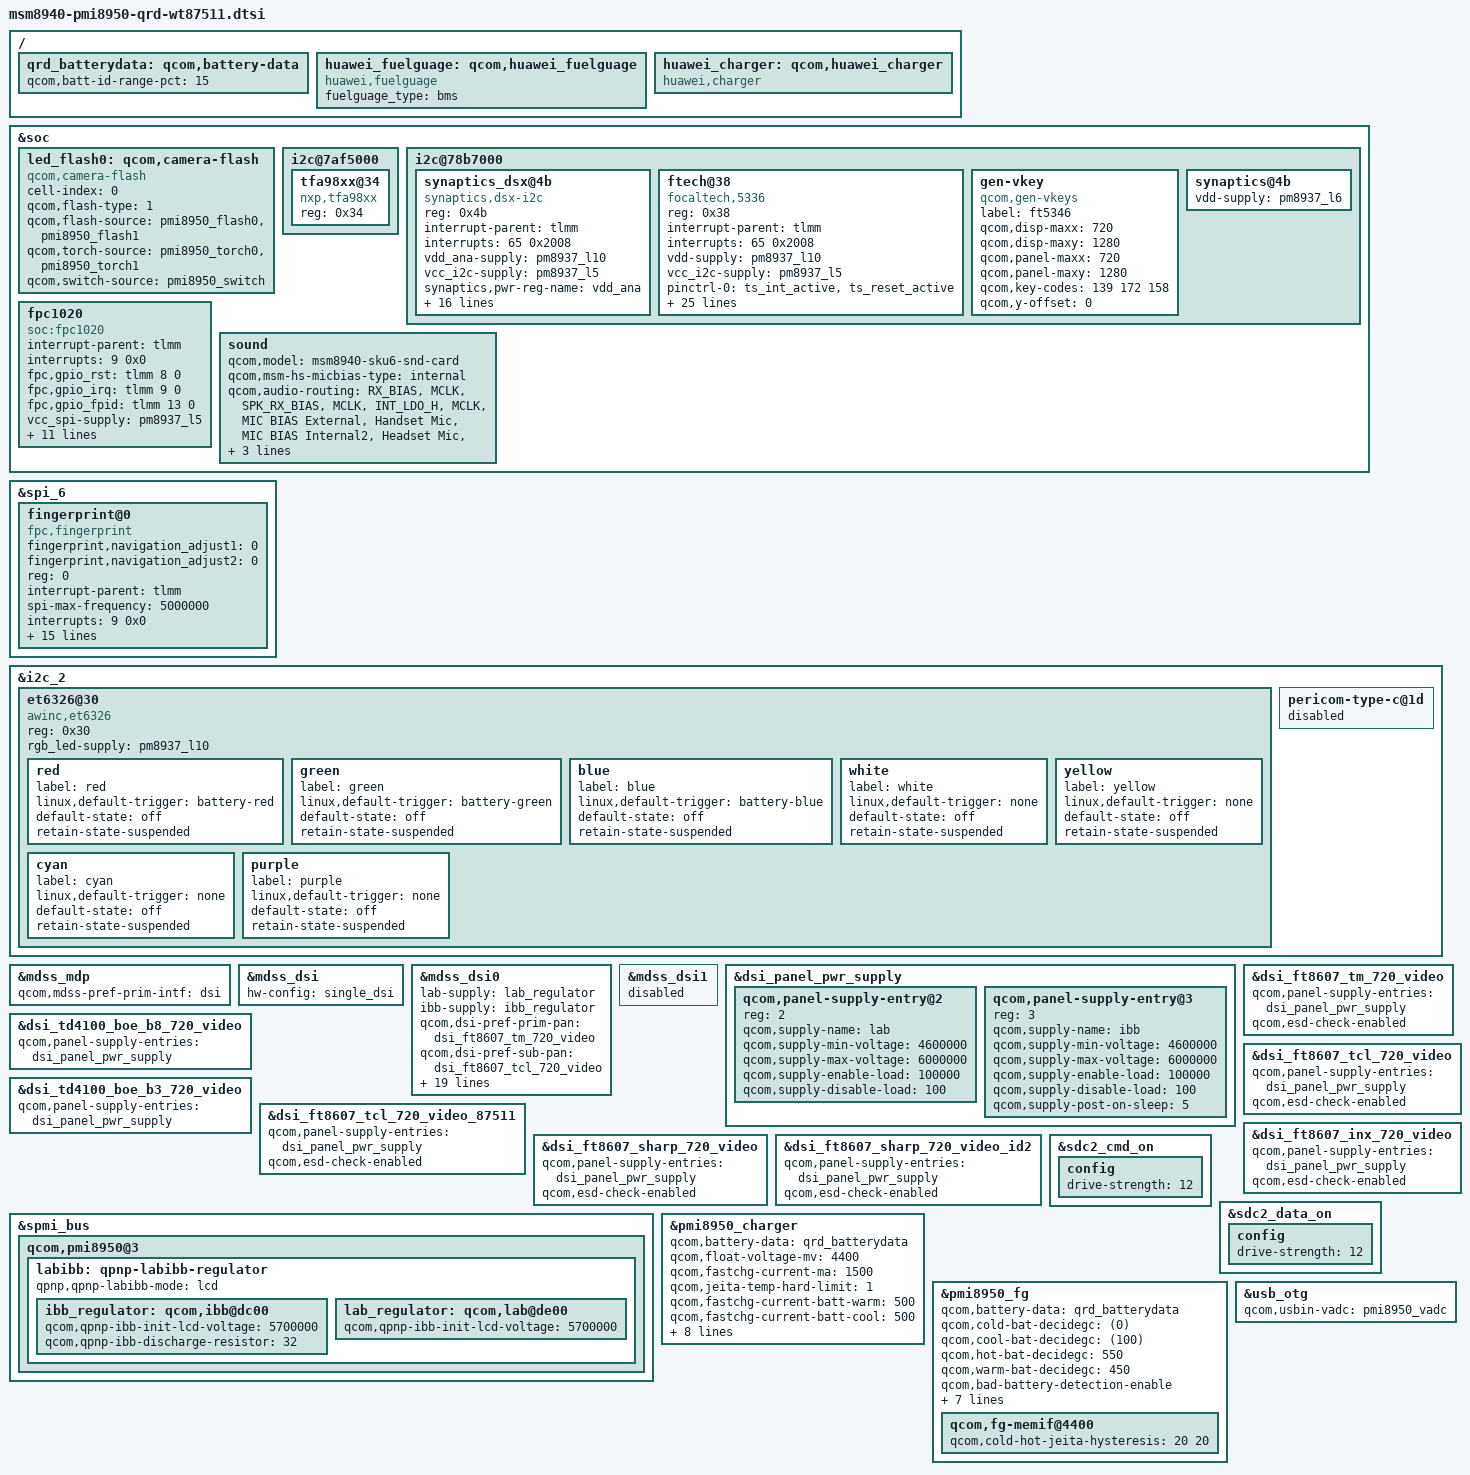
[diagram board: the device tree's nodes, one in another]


#include "msm8940.dtsi"
#include "msm-pmi8950.dtsi"
#include "msm8937-qrd.dtsi"
#include "msm8937-mdss-panels.dtsi"
#include "msm8937-camera-sensor-qrd.dtsi"
#include "dsi-panel-td4100-boe-720p-video.dtsi"
#include "dsi-panel-td4100-boe-b3-720p-video.dtsi"
#include "dsi-panel-td4100-boe-b8-720p-video.dtsi"
#include "dsi-panel-ft8607-tcl-720p-video.dtsi"
#include "dsi-panel-ft8607-tcl-720p-video-87511.dtsi"
#include "dsi-panel-ft8607-tm-720p-video.dtsi"
#include "dsi-panel-ft8607-inx-720p-video.dtsi"
#include "dsi-panel-ft8607-sharp-720p-video.dtsi"
#include "dsi-panel-ft8607-sharp-720p-video_id2.dtsi"
#include "msm8940-pinctrl.dtsi"

&soc {
	led_flash0: qcom,camera-flash {
		cell-index = <0>;
		compatible = "qcom,camera-flash";
		qcom,flash-type = <1>;
		qcom,flash-source = <&pmi8950_flash0 &pmi8950_flash1>;
		qcom,torch-source = <&pmi8950_torch0 &pmi8950_torch1>;
		qcom,switch-source = <&pmi8950_switch>;
	};
	i2c@7af5000{
		tfa98xx@34 { /*tfa9895 */
			 compatible = "nxp,tfa98xx";
			 reg = <0x34>;
			};
		};
	i2c@78b7000 {
		status = "ok";
		synaptics_dsx@4b {
			compatible = "synaptics,dsx-i2c";
			reg = <0x4b>;
			interrupt-parent = <&tlmm>;
			interrupts = <65 0x2008>;
			vdd_ana-supply = <&pm8937_l10>;
			vcc_i2c-supply = <&pm8937_l5>;
			synaptics,pwr-reg-name = "vdd_ana";
			synaptics,bus-reg-name = "vcc_i2c";
                        pinctrl-names = "pmx_ts_active","pmx_ts_suspend",
                                "pmx_ts_release";
                        pinctrl-0 = <&ts_int_active &ts_reset_active>;
                        pinctrl-1 = <&ts_int_suspend &ts_reset_suspend>;
                        pinctrl-2 = <&ts_release>;
			synaptics,irq-gpio = <&tlmm 65 0x2008>; /* IRQF_ONESHOT | IRQF_TRIGGER_LOW */
			synaptics,irq-on-state = <0>;
			synaptics,irq-flags = <0x2008>; /* IRQF_ONESHOT | IRQF_TRIGGER_LOW */

			synaptics,power-delay-ms = <200>;
			synaptics,reset-gpio = <&tlmm 64 0x00>;
			synaptics,reset-delay-ms = <200>;
			synaptics,reset-on-state = <0>;
			synaptics,reset-active-ms = <20>;
			synaptics,ub-i2c-addr = <0x2c>;
			synaptics,i2c-addr=<0x4b>;

			/* uncomment and update line below as appropriate if there are 0D buttons */
			/* synaptics,cap-button-codes = <102 158>; */
			/* uncomment and update lines below as appropriate if there are virtual buttons */
			/* synaptics,vir-button-codes = <102 100 900 100 60 158 300 900 100 60>; */
			/* synaptics,max-y-for-2d = <800>; */
			clock-names = "iface_clk", "core_clk";
			clocks = <&clock_gcc clk_gcc_blsp1_ahb_clk>,
				<&clock_gcc clk_gcc_blsp1_qup3_i2c_apps_clk>;
			};

		ftech@38 {
			compatible = "focaltech,5336";
			reg = <0x38>;
			interrupt-parent = <&tlmm>;
			interrupts = <65 0x2008>;
			vdd-supply = <&pm8937_l10>;
			vcc_i2c-supply = <&pm8937_l5>;
			/* pins used by touchscreen */
			pinctrl-names = "pmx_ts_active","pmx_ts_suspend",
				"pmx_ts_release";
			pinctrl-0 = <&ts_int_active &ts_reset_active>;
			pinctrl-1 = <&ts_int_suspend &ts_reset_suspend>;
			pinctrl-2 = <&ts_release>;
			ftech,name = "ft5336";
			ftech,family-id = <0x36>;
			ftech,reset-gpio = <&tlmm 64 0x00>;
			ftech,irq-gpio = <&tlmm 65 0x2008>;
			ftech,display-coords = <0 0 720 1280>;
			ftech,panel-coords = <0 0 720 1280>;
			/*ftech,button-map= <139 102 158>;*/
			ftech,virtual-key1 = <139 180 2000>;/*menu*/
			ftech,virtual-key2 = <172 540 2000>;/*home*/
			ftech,virtual-key3 = <158 900 2000>;/*back*/
			ftech,no-force-update;
			ftech,i2c-pull-up;
			ftech,group-id = <1>;
			ftech,hard-reset-delay-ms = <10>;
			ftech,soft-reset-delay-ms = <150>;
			ftech,num-max-touches = <10>;
			ftech,fw-delay-aa-ms = <30>;
			ftech,fw-delay-55-ms = <30>;
			ftech,fw-upgrade-id1 = <0x79>;
			ftech,fw-upgrade-id2 = <0x18>;
			ftech,fw-delay-readid-ms = <10>;
			ftech,fw-delay-era-flsh-ms = <2000>;
			ftech,fw-auto-cal;
			ftech,ignore-id-check;
			};

		gen-vkey {
			compatible = "qcom,gen-vkeys";
			label = "ft5346";
			qcom,disp-maxx = <720>;
			qcom,disp-maxy = <1280>;
			qcom,panel-maxx = <720>;
			qcom,panel-maxy = <1280>;
			qcom,key-codes = <139 172 158>;
			qcom,y-offset = <0>;
		};
	};
fpc1020 {
	compatible = "soc:fpc1020";

	interrupt-parent = <&tlmm>;
	interrupts = <9 0x0>;

	fpc,gpio_rst    = <&tlmm 8 0>;
	fpc,gpio_irq    = <&tlmm 9 0>;
	fpc,gpio_fpid      = <&tlmm 13 0>;

	vcc_spi-supply  = <&pm8937_l5>;
	vdd_ana-supply  = <&pm8937_l5>;
	vdd_io-supply   = <&pm8937_l5>;

	fpc,enable-on-boot;
	/delete-property/
	fpc,enable-wakeup;

	fpc,spi-max-frequency = <4800000>;

	/* Only for SPI Clock Handled by Linux */
	clock-names = "iface_clk", "core_clk";
	clocks = <&clock_gcc clk_gcc_blsp1_ahb_clk>,
		<&clock_gcc clk_gcc_blsp1_qup1_spi_apps_clk>;

	pinctrl-names = "fpc1020_spi_active",
			"fpc1020_reset_reset",
			"fpc1020_reset_active",
			"fpc1020_irq_active",
	                 "fpc1020_id_gpio";

	pinctrl-0 = <&fpc_spi_active>;
	pinctrl-1 = <&fpc_reset_reset>;
	pinctrl-2 = <&fpc_reset_active>;
	pinctrl-3 = <&fpc_irq_active>;
	pinctrl-4 = <&fp_id_gpio>;
	
	};
};

&spi_6{
	status = "ok";
	fingerprint@0 {
		compatible = "fpc,fingerprint";
		fingerprint,navigation_adjust1 = <0>;
		fingerprint,navigation_adjust2 = <0>;
		reg = <0>;
		interrupt-parent = <&tlmm>;
		spi-max-frequency = <5000000>;
		interrupts = <9 0x0>;
		fingerprint,irq_gpio = <&tlmm 9 0>;
		fingerprint,reset_gpio = <&tlmm 8 0>;
		fingerprint,moduleid_gpio = <&tlmm 13 0>;
		fingerprint,moduleid_high = "CT";
		fingerprint,moduleid_low = "OF";
		fingerprint,moduleid_float = "PR";
		vcc_spi-supply  = <&pm8937_l5>;
	       vdd_ana-supply  = <&pm8937_l5>;
	       vdd_io-supply   = <&pm8937_l5>;
		fingerprint,vdd = "vdd";
		pinctrl-names = "default", "idle";
		pinctrl-0 = <&fingerprint_moduleid_default &fingerprint_reset_default &fingerprint_ldo_default &fingerprint_irq_active>;
		pinctrl-1 = <&fingerprint_moduleid_idle>;
		status = "ok";
	};
};
&i2c_2  { /* i2c 6 */
	et6326@30 { /*blink */
		compatible = "awinc,et6326";
		reg = <0x30>;
		rgb_led-supply = <&pm8937_l10>;
		
		red {
			label = "red";
			linux,default-trigger = "battery-red";
			default-state = "off";
			retain-state-suspended;
		};

		green {
			label = "green";
			linux,default-trigger = "battery-green";
			default-state = "off";
			retain-state-suspended;
		};

		blue {
			label = "blue";
			linux,default-trigger = "battery-blue";
			default-state = "off";
			retain-state-suspended;
		};
		white {
			label = "white";
			linux,default-trigger = "none";
			default-state = "off";
			retain-state-suspended;
		};

		yellow {
			label = "yellow";
			linux,default-trigger = "none";
			default-state = "off";
			retain-state-suspended;
		};

		cyan {
			label = "cyan";
			linux,default-trigger = "none";
			default-state = "off";
			retain-state-suspended;
		};
		purple {
			label = "purple";
			linux,default-trigger = "none";
			default-state = "off";
			retain-state-suspended;
		};				
		
	};
};
&mdss_mdp {
	qcom,mdss-pref-prim-intf = "dsi";
};

&mdss_dsi {
	hw-config = "single_dsi";
};

&mdss_dsi0 {
	lab-supply = <&lab_regulator>;
	ibb-supply = <&ibb_regulator>;

	qcom,dsi-pref-prim-pan = <&dsi_ft8607_tm_720_video>;
        qcom,dsi-pref-sub-pan = <&dsi_ft8607_tcl_720_video>;
	qcom,dsi-pref-sub1-pan = <&dsi_td4100_boe_b3_720_video>;
	qcom,dsi-pref-sub2-pan = <&dsi_td4100_boe_b8_720_video>;
	qcom,dsi-pref-sub3-pan = <&dsi_ft8607_inx_720_video>;
	qcom,dsi-pref-sub4-pan = <&dsi_ft8607_sharp_720_video>;
	qcom,dsi-pref-sub5-pan = <&dsi_ft8607_sharp_720_video_id2>;
	qcom,dsi-pref-sub6-pan = <&dsi_ft8607_tcl_720_video_87511>;
	pinctrl-names = "mdss_default", "mdss_sleep";
	pinctrl-0 = <&mdss_dsi_active &mdss_te_active>;
	pinctrl-1 = <&mdss_dsi_suspend &mdss_te_suspend>;

	qcom,platform-te-gpio = <&tlmm 24 0>;
	qcom,platform-reset-gpio = <&tlmm 60 0>;

        qcom,regulator-ldo-mode;
        qcom,platform-regulator-settings = [ 00 01 01 00 20 07 00];
};

&mdss_dsi1 {
	status = "disabled";
};

&labibb {
	status = "ok";
	qpnp,qpnp-labibb-mode = "lcd";
};

&ibb_regulator {
	qcom,qpnp-ibb-discharge-resistor = <32>;
};

&dsi_panel_pwr_supply {
	qcom,panel-supply-entry@2 {
		reg = <2>;
		qcom,supply-name = "lab";
		qcom,supply-min-voltage = <4600000>;
		qcom,supply-max-voltage = <6000000>;
		qcom,supply-enable-load = <100000>;
		qcom,supply-disable-load = <100>;
	};

	qcom,panel-supply-entry@3 {
		reg = <3>;
		qcom,supply-name = "ibb";
		qcom,supply-min-voltage = <4600000>;
		qcom,supply-max-voltage = <6000000>;
		qcom,supply-enable-load = <100000>;
		qcom,supply-disable-load = <100>;
		qcom,supply-post-on-sleep = <5>;
	};
};

&dsi_ft8607_tm_720_video {
	qcom,panel-supply-entries = <&dsi_panel_pwr_supply>;
	qcom,esd-check-enabled;
};
&dsi_td4100_boe_b8_720_video {
        qcom,panel-supply-entries = <&dsi_panel_pwr_supply>;
};
&dsi_td4100_boe_b3_720_video {
        qcom,panel-supply-entries = <&dsi_panel_pwr_supply>;
};
&dsi_ft8607_tcl_720_video {
	qcom,panel-supply-entries = <&dsi_panel_pwr_supply>;
	qcom,esd-check-enabled;
};
&dsi_ft8607_tcl_720_video_87511 {
	qcom,panel-supply-entries = <&dsi_panel_pwr_supply>;
	qcom,esd-check-enabled;
};
&dsi_ft8607_inx_720_video {
	qcom,panel-supply-entries = <&dsi_panel_pwr_supply>;
	qcom,esd-check-enabled;
};
&dsi_ft8607_sharp_720_video {
	qcom,panel-supply-entries = <&dsi_panel_pwr_supply>;
	qcom,esd-check-enabled;
};
&dsi_ft8607_sharp_720_video_id2 {
	qcom,panel-supply-entries = <&dsi_panel_pwr_supply>;
	qcom,esd-check-enabled;
};
&spmi_bus {
	qcom,pmi8950@3 {
		labibb: qpnp-labibb-regulator {
			ibb_regulator: qcom,ibb@dc00 {
				/delete-property/
					qcom,qpnp-ibb-use-default-voltage;
				qcom,qpnp-ibb-init-lcd-voltage = <5700000>;
			};

			lab_regulator: qcom,lab@de00 {
				/delete-property/
					qcom,qpnp-ibb-use-default-voltage;
				qcom,qpnp-ibb-init-lcd-voltage = <5700000>;
			};
		};
	};
};

&sdc2_cmd_on {
	config {
		drive-strength = <12>;
	};
};

&sdc2_data_on {
	config {
		drive-strength = <12>;
	};
};
/*Other, xieyue.wt, DEL, 2016-06-02, Need flash1,touch1 node*/
/*
&flash_led {
	/delete-node/ qcom,flash_1;
	/delete-node/ qcom,torch_1;
};
*/

/ {
	qrd_batterydata: qcom,battery-data {
		qcom,batt-id-range-pct = <15>;//xjb.wt 20160706 .battery ID rang percent.
		#include "batterydata-diego-costlight-4v4-3020mah.dtsi"
		#include "batterydata-diego-sunwoda-4v4-3020mah.dtsi"
		#include "batterydata-diego-desay-4v4-3020mah.dtsi"
		#include "batterydata-diego-sucd-4v4-3020mah.dtsi"
		#include "batterydata-diego-sucd-costlight-4v4-3020mah.dtsi"
	};
};

&pmi8950_charger {
	qcom,battery-data = <&qrd_batterydata>;
	qcom,float-voltage-mv = <4400>;
	qcom,fastchg-current-ma = <1500>;  //xjb.wt 20160706 .charging current.
	//qcom,chg-led-sw-controls;
	//qcom,chg-led-support;
	status = "okay";
	qcom,jeita-temp-hard-limit = <1>;
	qcom,fastchg-current-batt-warm = <500>;
	qcom,fastchg-current-batt-cool = <500>;
	qcom,vfloat-batt-warm = <4100>;
	qcom,device-not-support-hvdcp;
	qcom,float-voltage-comp = <16>;
	qcom,fastchg-current-customize-cool = <300>;
	qcom,customize-cool-lower-limit = <0>;
	qcom,customize-cool-upper-limit = <50>;
	qcom,override-usb-current;
	qcom,not-set-usb-online;
};

&pmi8950_fg {
	qcom,battery-data = <&qrd_batterydata>;
	qcom,cold-bat-decidegc = <(0)>;
	qcom,cool-bat-decidegc = <(100)>;
	qcom,hot-bat-decidegc = <550>;
	qcom,warm-bat-decidegc = <450>;
	qcom,bad-battery-detection-enable;
	qcom,hold-soc-while-full;
	qcom,vbat-estimate-diff-mv = <100>;
	qcom,fg-cutoff-voltage-mv = <3380>;
	qcom,resume-soc = <99>;
	qcom,resume-soc-raw = <253>;
	qcom,device-not-support-hvdcp;
	qcom,ext-sense-type;
	qcom,fg-memif@4400 {
		qcom,cold-hot-jeita-hysteresis = <20 20>;
	};
};

&usb_otg {
	qcom,usbin-vadc = <&pmi8950_vadc>;
};

/{
	huawei_fuelguage: qcom,huawei_fuelguage{
		compatible = "huawei,fuelguage";
		fuelguage_type = "bms";
		status = "okay";
	};
};
/{
	huawei_charger: qcom,huawei_charger{
		compatible = "huawei,charger";
		status = "okay";
	};
};

&soc {
	sound {
		qcom,model = "msm8940-sku6-snd-card";
		qcom,msm-hs-micbias-type = "internal";
		qcom,audio-routing =
			"RX_BIAS", "MCLK",
			"SPK_RX_BIAS", "MCLK",
			"INT_LDO_H", "MCLK",
			"MIC BIAS External", "Handset Mic",
			"MIC BIAS Internal2", "Headset Mic",
			"MIC BIAS External", "Secondary Mic",
			"AMIC1", "MIC BIAS External",
			"AMIC2", "MIC BIAS Internal2",
			"AMIC3", "MIC BIAS External";
	};

	i2c@78b7000 {
		synaptics@4b {
			vdd-supply = <&pm8937_l6>;
		};
	};
};

&i2c_2 {
	pericom-type-c@1d {
		status="disabled";
	};
};
